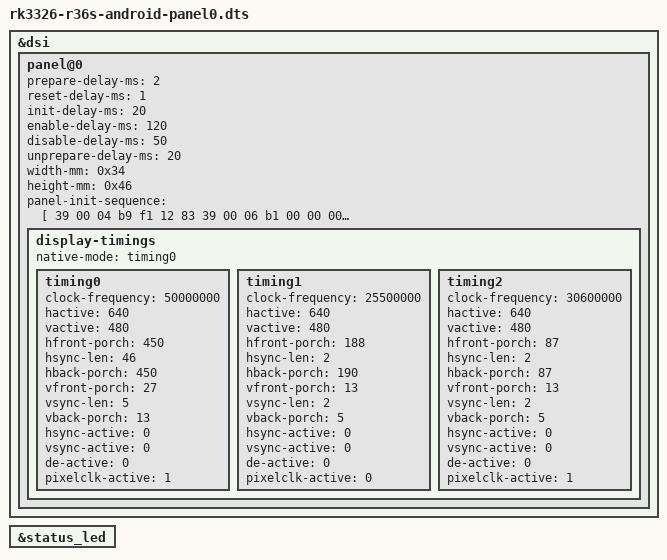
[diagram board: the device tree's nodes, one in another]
// SPDX-License-Identifier: (GPL-2.0+ OR MIT)
/*
 * Copyright (c) 2020 Hardkernel Co., Ltd
 */

/dts-v1/;
#include "rk3326-r36s-android.dtsi"


&dsi {
	panel@0 {
		prepare-delay-ms = <2>;
		reset-delay-ms = <1>;
		init-delay-ms = <20>;
		enable-delay-ms = <120>;
		disable-delay-ms = <50>;
		unprepare-delay-ms = <20>;
		width-mm = <0x34>;
		height-mm = <0x46>;
		panel-init-sequence = [
		39 00 04 b9 f1 12 83 
		39 00 06 b1 00 00 00 da 80 
		39 00 04 b2 00 13 70 
		39 00 0b b3 10 10 28 28 03 ff 00 00 00 00 
		15 00 02 b4 80 15 00 03 b5 0a 0a 
		15 00 03 b6 7f 7f 
		39 00 05 b8 26 62 f0 63
		39 00 1c ba 33 81 05 f9 0e 0e 20 00 00 00 00 00 00 00 44 25 00 90 0a 00 00 01 4f 01 00 00 37 
		15 00 02 bc 47 
		39 00 04 bf 02 11 00 
		39 00 0a c0 73 73 50 50 00 00 12 50 00 
		39 00 0d c1 53 c0 32 32 77 e1 dd dd 77 77 33 33 
		39 00 07 c6 82 00 bf ff 00 ff 
		39 00 07 c7 b8 00 0a 00 00 00 
		39 00 05 c8 10 40 1e 02 
		15 00 02 cc 0b 
		39 00 23 e0 00 07 0d 37 35 3f 41 44 06 0c 0d 0f 11 10 12 14 1a 00 07 0d 37 35 3f 41 44 06 0c 0d 0f 11 10 12 14 1a 
		39 00 0f e3 07 07 0b 0b 0b 0b 00 00 00 00 ff 00 c0 10 
		39 00 40 e9 c8 10 02 00 00 b0 b1 11 31 23 28 80 b0 b1 27 08 00 04 02 00 00 00 00 04 02 00 00 00 88 88 ba 60 24 08 88 88 88 88 88 88 88 ba 71 35 18 88 88 88 88 88 00 00 00 01 00 00 00 00 00 00 00 00 00 
		39 00 3e ea 97 0a 82 02 03 07 00 00 00 00 00 00 81 88 ba 17 53 88 88 88 88 88 88 80 88 ba 06 42 88 88 88 88 88 88 23 00 00 02 80 00 00 00 00 00 00 00 00 00 00 00 00 00 00 00 00 00 00 00 00 00 00 
		39 00 04 ef ff ff 01 
		05 c8 01 11 
		05 32 01 29
		];

			display-timings {
				native-mode = <&timing0>;

				timing0 {
					clock-frequency = <50000000>;
					hactive = <640>;
					vactive = <480>;
					hfront-porch = <450>;
					hsync-len = <46>;
					hback-porch = <450>;
					vfront-porch = <27>;	/* was 17: 61.2 Hz; 60.05 Hz, same pixel clock */
					vsync-len = <5>;
					vback-porch = <13>;
					hsync-active = <0>;
					vsync-active = <0>;
					de-active = <0>;
					pixelclk-active = <1>;
				};

				timing1 {
					clock-frequency = <25500000>;
					hactive = <640>;
					vactive = <480>;
					hfront-porch = <188>;
					hsync-len = <2>;
					hback-porch = <190>;
					vfront-porch = <13>;
					vsync-len = <2>;
					vback-porch = <5>;
					hsync-active = <0>;
					vsync-active = <0>;
					de-active = <0>;
					pixelclk-active = <0>;
				};

				timing2 {
					clock-frequency = <30600000>;
					hactive = <640>;
					vactive = <480>;
					hfront-porch = <87>;
					hsync-len = <2>;
					hback-porch = <87>;
					vfront-porch = <13>;
					vsync-len = <2>;
					vback-porch = <5>;
					hsync-active = <0>;
					vsync-active = <0>;
					de-active = <0>;
					pixelclk-active = <1>;
				};
			};
	};
};

&status_led {
	status = "okay";
};
